# ATmega8515 register map
Vendor: Atmel; File version: 1.0
CPU: other r0p0, little endian, no MPU, no FPU, 4 interrupt priority bits
Registers are 8-bit, read-write, reset 0x0 unless marked. A register's access mark holds for its fields unless they carry their own. Offsets are from the block's base; lines under a group give offsets from that group; [hi:lo] are bit positions; {n}, {i} and the like mark numbered series; 'fields as' and 'values as' point back to an identical list; <NAME> marks a mode.

## Memory map
0x00800024 CPU blocks up to offset 0x3C — CPU Registers
0x00800025 PORTE size 0x3 — I/O Port
0x00800028 AC size 0x1 — Analog Comparator
0x00800029 USART blocks up to offset 0x18
0x0080002D SPI size 0x3 — Serial Peripheral Interface
0x00800030 PORTD size 0x3 — I/O Port
0x00800033 PORTC size 0x3 — I/O Port
0x00800036 PORTB size 0x3 — I/O Port
0x00800039 PORTA size 0x3 — I/O Port
0x0080003C EEPROM size 0x4
0x00800041 WDT size 0x1 — Watchdog Timer
0x00800044 TC1 blocks up to offset 0x16 — Timer/Counter, 16-bit
0x00800051 TC0 blocks up to offset 0x9 — Timer/Counter, 8-bit
0x0080005A EXINT size 0x2 — External Interrupts

## Interrupts
0 RESET (CPU) — External Reset, Power-on Reset and Watchdog Reset
1 INT0 (CPU) — External Interrupt Request 0
2 INT1 (CPU) — External Interrupt Request 1
3 TIMER1_CAPT (CPU) — Timer/Counter1 Capture Event
4 TIMER1_COMPA (CPU) — Timer/Counter1 Compare Match A
5 TIMER1_COMPB (CPU) — Timer/Counter1 Compare MatchB
6 TIMER1_OVF (CPU) — Timer/Counter1 Overflow
7 TIMER0_OVF (CPU) — Timer/Counter0 Overflow
8 SPI_STC (CPU) — Serial Transfer Complete
9 USART_RX (CPU) — USART, Rx Complete
10 USART_UDRE (CPU) — USART Data Register Empty
11 USART_TX (CPU) — USART, Tx Complete
12 ANA_COMP (CPU) — Analog Comparator
13 INT2 (CPU) — External Interrupt Request 2
14 TIMER0_COMP (CPU) — Timer 0 Compare Match
15 EE_RDY (CPU) — EEPROM Ready
16 SPM_RDY (CPU) — Store Program Memory Ready

## AC — Analog Comparator
Base 0x00800028
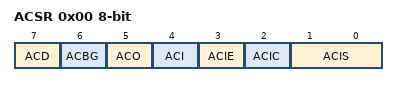
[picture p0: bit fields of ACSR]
0x00 ACSR — Analog Comparator Control And Status Register (read-only for debugger)
  [7] ACD — Analog Comparator Disable
  [6] ACBG — Analog Comparator Bandgap Select
  [5] ACO — Analog Compare Output
  [4] ACI — Analog Comparator Interrupt Flag
  [3] ACIE — Analog Comparator Interrupt Enable
  [2] ACIC — Analog Comparator Input Capture Enable
  [1:0] ACIS — Analog Comparator Interrupt Mode Select bits
    0=INTERRUPT_ON_TOGGLE; 2=INTERRUPT_ON_FALLING_EDGE; 3=INTERRUPT_ON_RISING_EDGE

## CPU — CPU Registers
Base 0x00800024
0x00 OSCCAL — Oscillator Calibration Value
  [7:0] OSCCAL — Oscillator Calibration
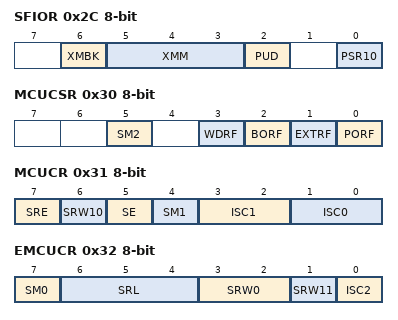
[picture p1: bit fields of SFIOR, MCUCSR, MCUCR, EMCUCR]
0x2C SFIOR — Special Function IO Register
  [6] XMBK — External Memory Bus Keeper Enable
  [5:3] XMM — External Memory High Mask Bits
  [2] PUD — Pull-up Disable
  [0] PSR10 — Prescaler Reset Timer / Counter 1 and Timer / Counter 0
0x30 MCUCSR — MCU Control And Status Register
  [5] SM2 — Sleep Mode Select Bit 2
  [3] WDRF — Watchdog Reset Flag
  [2] BORF — Brown-out Reset Flag
  [1] EXTRF — External Reset Flag
  [0] PORF — Power-on reset flag
0x31 MCUCR — MCU Control Register
  [7] SRE — External SRAM/XMEM Enable
  [6] SRW10 — Wait State Select Bits for Upper Sector, bit 0
  [5] SE — Sleep Enable
  [4] SM1 — Sleep Mode Select Bit 1
  [3:2] ISC1 — Interrupt Sense Control 1 Bits
    0=LOW_LEVEL_OF_INTX; 1=ANY_LOGICAL_CHANGE_IN_INTX; 2=FALLING_EDGE_OF_INTX; 3=RISING_EDGE_OF_INTX
  [1:0] ISC0 — Interrupt Sense Control 0 Bits
    values as ISC1
0x32 EMCUCR — Extended MCU Control Register
  [7] SM0 — Sleep Mode Select Bit 0
  [6:4] SRL — Wait State Selector Limit bits
    0=LS_N_A_US_0X1100_0XFFFF; 1=LS_0X1100_0X1FFF_US_0X2000_0XFFFF; 2=LS_0X1100_0X3FFF_US_0X4000_0XFFFF; 3=LS_0X1100_0X5FFF_US_0X6000_0XFFFF; 4=LS_0X1100_0X7FFF_US_0X8000_0XFFFF; 5=LS_0X1100_0X9FFF_US_0XA000_0XFFFF; 6=LS_0X1100_0XBFFF_US_0XC000_0XFFFF; 7=LS_0X1100_0XDFFF_US_0XE000_0XFFFF
  [3:2] SRW0 — Wait State Select Bits for Lower Sector, bits
    0=NO_WAIT_STATES; 1=WAIT_ONE_CYCLE_DURING_READ_WRITE_STROBE; 2=WAIT_TWO_CYCLES_DURING_READ_WRITE_STROBE; 3=WAIT_TWO_CYCLES_DURING_READ_WRITE_AND_WAIT_ONE_CYCLE_BEFORE_DRIVING_OUT_NEW_ADDRESS
  [1] SRW11 — Wait State Select Bits for Upper Sector, bit 1
  [0] ISC2 — Interrupt Sense Control 2
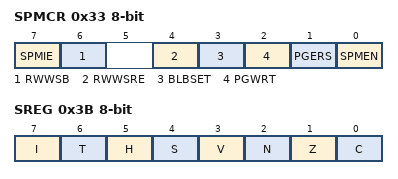
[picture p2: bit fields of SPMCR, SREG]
0x33 SPMCR — Store Program Memory Control Register
  [7] SPMIE — SPM Interrupt Enable
  [6] RWWSB — Read-While-Write Section Busy
  [4] RWWSRE — Read-While-Write Section Read Enable
  [3] BLBSET — Boot Lock Bit Set
  [2] PGWRT — Page Write
  [1] PGERS — Page Erase
  [0] SPMEN — Store Program Memory Enable
0x39 SP 16-bit (reset mask 0xFF) — Stack Pointer
0x3B SREG — Status Register
  [7] I — Global Interrupt Enable
  [6] T — Bit Copy Storage
  [5] H — Half Carry Flag
  [4] S — Sign Bit
  [3] V — Two's Complement Overflow Flag
  [2] N — Negative Flag
  [1] Z — Zero Flag
  [0] C — Carry Flag
